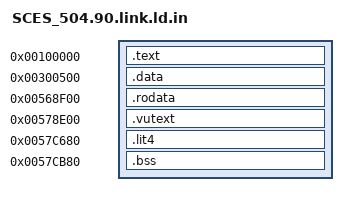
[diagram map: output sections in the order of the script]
/* Hand-written: splat's generated script groups by section type, but this ELF
   interleaves text/data/rodata/vutext/lit4 at fixed addresses. */
INCLUDE config/undefined_syms_auto.txt
INCLUDE config/undefined_funcs_auto.txt
/* Projection work backing view starts inside an existing BSS allocation. */
D_00600110 = 0x00600110;
D_0069247A = 0x0069247a;
D_0057CB88 = 0x0057cb88;
D_0057CB8C = 0x0057cb8c;
/* data inside .text that splat folds into padding: absolute aliases */
func_0017A540 = 0x17A540;
/* ee-gcc soft-float libcall names (what the compiler emits for double arithmetic/conversions) */
dpadd = func_002EBBB0;
dpsub = func_002EBC08;
dpdiv = func_002EBF18;
dpcmp = func_002EC198;
litodp = func_002EC1E8;
dptoli = 0x2EC2A0;
dptoul = func_002EC338;
dptofp = func_002EC440;
fptoui = 0x2ECF38;
fptodp = func_002ED038;
sqrtf = 0x2E9708;
__fixdfdi = 0x300350;
__fixunssfdi = func_002EA358;
__udivdi3 = func_002EAC90;
__umoddi3 = func_002EB260;
__muldi3 = func_002EAC30;
SECTIONS
{
    . = 0x100000;
    .text : {
@TEXT_OBJS@
    }
    . = 0x300500;
    .data : { build/asm/data/data.data.s.o(.data) }
    . = 0x568f00;
    .rodata : SUBALIGN(1) {   /* every piece/table is placed by an explicit `. = ADDR` */
@RODATA_OBJS@
    }
    . = 0x578e00;
    .vutext : { build/assets/vutext.bin.o(.data) }
    . = 0x57c680;
    .lit4 : SUBALIGN(4) { build/asm/data/lit4.data.s.o(.data) }
    . = 0x57cb80;
    .bss (NOLOAD) : { build/asm/data/47DB0C.bss.s.o(.bss) }
    /DISCARD/ : { *(.MIPS.abiflags) *(.reginfo) *(.gnu.attributes) *(.comment) *(.pdr) *(.mdebug*) }
}

/* Existing data points inside the full 122-entry character jump table. */
D_005699AC = 0x005699AC;

/* EE compiler helpers used by unsigned double-to-integer conversion. */
dpmul = func_002EBC70;
__floatdidf = func_002EA450;
